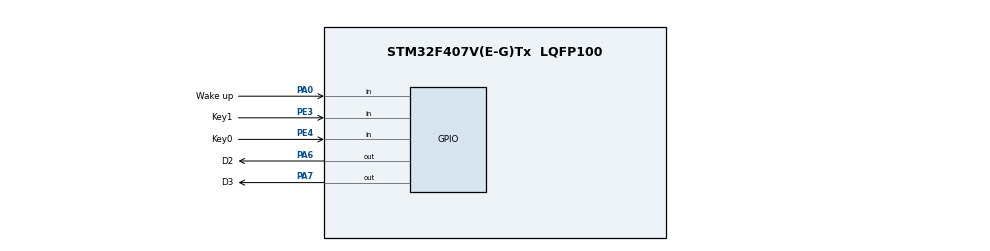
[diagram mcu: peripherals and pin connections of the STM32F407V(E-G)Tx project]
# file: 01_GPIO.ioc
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Mcu.Family=STM32F4
Mcu.Name=STM32F407V(E-G)Tx
Mcu.Package=LQFP100
NVIC.PriorityGroup=NVIC_PRIORITYGROUP_4
PA0-WKUP.GPIO_Label=Wake up
PA0-WKUP.GPIO_PuPd=GPIO_PULLDOWN
PA0-WKUP.Signal=GPIO_Input
PA13.Mode=Serial_Wire
PA13.Signal=SYS_JTMS-SWDIO
PA14.Mode=Serial_Wire
PA14.Signal=SYS_JTCK-SWCLK
PA6.GPIO_Label=D2
PA6.GPIO_Speed=GPIO_SPEED_FREQ_VERY_HIGH
PA6.PinState=GPIO_PIN_SET
PA6.Signal=GPIO_Output
PA7.GPIO_Label=D3
PA7.GPIO_Speed=GPIO_SPEED_FREQ_VERY_HIGH
PA7.PinState=GPIO_PIN_SET
PA7.Signal=GPIO_Output
PE3.GPIO_Label=Key1
PE3.GPIO_PuPd=GPIO_PULLUP
PE3.Signal=GPIO_Input
PE4.GPIO_Label=Key0
PE4.GPIO_PuPd=GPIO_PULLUP
PE4.Signal=GPIO_Input
PH0-OSC_IN.Mode=HSE-External-Oscillator
PH0-OSC_IN.Signal=RCC_OSC_IN
PH1-OSC_OUT.Mode=HSE-External-Oscillator
PH1-OSC_OUT.Signal=RCC_OSC_OUT
ProjectManager.HeapSize=0x200
ProjectManager.StackSize=0x400
ProjectManager.TargetToolchain=MDK-ARM V5.27
RCC.48MHZClocksFreq_Value=84000000
RCC.AHBFreq_Value=168000000
RCC.APB1CLKDivider=RCC_HCLK_DIV4
RCC.APB1Freq_Value=42000000
RCC.APB1TimFreq_Value=84000000
RCC.APB2CLKDivider=RCC_HCLK_DIV2
RCC.APB2Freq_Value=84000000
RCC.APB2TimFreq_Value=168000000
RCC.CortexFreq_Value=168000000
RCC.HCLKFreq_Value=168000000
RCC.HSE_VALUE=8000000
RCC.HSI_VALUE=16000000
RCC.LSE_VALUE=32768
RCC.PLLM=8
RCC.PLLN=336
RCC.PLLSourceVirtual=RCC_PLLSOURCE_HSE
RCC.SYSCLKFreq_VALUE=168000000
RCC.SYSCLKSource=RCC_SYSCLKSOURCE_PLLCLK
RCC.VCOOutputFreq_Value=336000000
board=custom

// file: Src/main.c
/* USER CODE BEGIN Header */
/**
  ******************************************************************************
  * @file           : main.c
  * @brief          : Main program body
  ******************************************************************************
  * @attention
  *
  * <h2><center>&copy; Copyright (c) 2020 STMicroelectronics.
  * All rights reserved.</center></h2>
  *
  * This software component is licensed by ST under BSD 3-Clause license,
  * the "License"; You may not use this file except in compliance with the
  * License. You may obtain a copy of the License at:
  *                        opensource.org/licenses/BSD-3-Clause
  *
  ******************************************************************************
  */
/* USER CODE END Header */

#include "main.h"

void SystemClock_Config(void);
static void MX_GPIO_Init(void);

int main(void)
{

  /* MCU Configuration--------------------------------------------------------*/

  /* Reset of all peripherals, Initializes the Flash interface and the Systick. */

  LL_APB2_GRP1_EnableClock(LL_APB2_GRP1_PERIPH_SYSCFG);
  LL_APB1_GRP1_EnableClock(LL_APB1_GRP1_PERIPH_PWR);

  NVIC_SetPriorityGrouping(NVIC_PRIORITYGROUP_4);

  /* System interrupt init*/

  /* Configure the system clock */
  SystemClock_Config();

  /* Initialize all configured peripherals */
  MX_GPIO_Init();

  /* Infinite loop */
  while (1)
  {

    /* USER CODE BEGIN 3 */

		// LL_GPIO_TogglePin(GPIOA, LL_GPIO_PIN_6);
		// LL_GPIO_WriteOutputPort(GPIOA, 0x0000);

		if(!(LL_GPIO_ReadInputPort(GPIOE) & 0x0008))
		{
			//LL_GPIO_WriteOutputPort(GPIOA, 0x0000);
			LL_GPIO_SetOutputPin(GPIOA, LL_GPIO_PIN_6);
		}
		else
			//LL_GPIO_WriteOutputPort(GPIOA, 0x0040);
			LL_GPIO_ResetOutputPin(GPIOA, LL_GPIO_PIN_6);
  }
  /* USER CODE END 3 */
}

void SystemClock_Config(void)
{
  LL_FLASH_SetLatency(LL_FLASH_LATENCY_5);

  if(LL_FLASH_GetLatency() != LL_FLASH_LATENCY_5)
  {
  Error_Handler();
  }
  LL_PWR_SetRegulVoltageScaling(LL_PWR_REGU_VOLTAGE_SCALE1);
  LL_RCC_HSE_Enable();

   /* Wait till HSE is ready */
  while(LL_RCC_HSE_IsReady() != 1)
  {

  }
  LL_RCC_PLL_ConfigDomain_SYS(LL_RCC_PLLSOURCE_HSE, LL_RCC_PLLM_DIV_8, 336, LL_RCC_PLLP_DIV_2);
  LL_RCC_PLL_Enable();

   /* Wait till PLL is ready */
  while(LL_RCC_PLL_IsReady() != 1)
  {

  }
  LL_RCC_SetAHBPrescaler(LL_RCC_SYSCLK_DIV_1);
  LL_RCC_SetAPB1Prescaler(LL_RCC_APB1_DIV_4);
  LL_RCC_SetAPB2Prescaler(LL_RCC_APB2_DIV_2);
  LL_RCC_SetSysClkSource(LL_RCC_SYS_CLKSOURCE_PLL);

   /* Wait till System clock is ready */
  while(LL_RCC_GetSysClkSource() != LL_RCC_SYS_CLKSOURCE_STATUS_PLL)
  {

  }
  LL_Init1msTick(168000000);
  LL_SetSystemCoreClock(168000000);
}

static void MX_GPIO_Init(void)
{
  LL_GPIO_InitTypeDef GPIO_InitStruct = {0};

  /* GPIO Ports Clock Enable */
  LL_AHB1_GRP1_EnableClock(LL_AHB1_GRP1_PERIPH_GPIOE);
  LL_AHB1_GRP1_EnableClock(LL_AHB1_GRP1_PERIPH_GPIOH);
  LL_AHB1_GRP1_EnableClock(LL_AHB1_GRP1_PERIPH_GPIOA);

  /**/
  LL_GPIO_SetOutputPin(GPIOA, D2_Pin|D3_Pin);

  /**/
  GPIO_InitStruct.Pin = Key1_Pin|Key0_Pin;
  GPIO_InitStruct.Mode = LL_GPIO_MODE_INPUT;
  GPIO_InitStruct.Pull = LL_GPIO_PULL_UP;
  LL_GPIO_Init(GPIOE, &GPIO_InitStruct);

  /**/
  GPIO_InitStruct.Pin = Wake_up_Pin;
  GPIO_InitStruct.Mode = LL_GPIO_MODE_INPUT;
  GPIO_InitStruct.Pull = LL_GPIO_PULL_DOWN;
  LL_GPIO_Init(Wake_up_GPIO_Port, &GPIO_InitStruct);

  /**/
  GPIO_InitStruct.Pin = D2_Pin|D3_Pin;
  GPIO_InitStruct.Mode = LL_GPIO_MODE_OUTPUT;
  GPIO_InitStruct.Speed = LL_GPIO_SPEED_FREQ_VERY_HIGH;
  GPIO_InitStruct.OutputType = LL_GPIO_OUTPUT_PUSHPULL;
  GPIO_InitStruct.Pull = LL_GPIO_PULL_NO;
  LL_GPIO_Init(GPIOA, &GPIO_InitStruct);

}

void Error_Handler(void)
{
}

/************************ (C) COPYRIGHT STMicroelectronics *****END OF FILE****/
